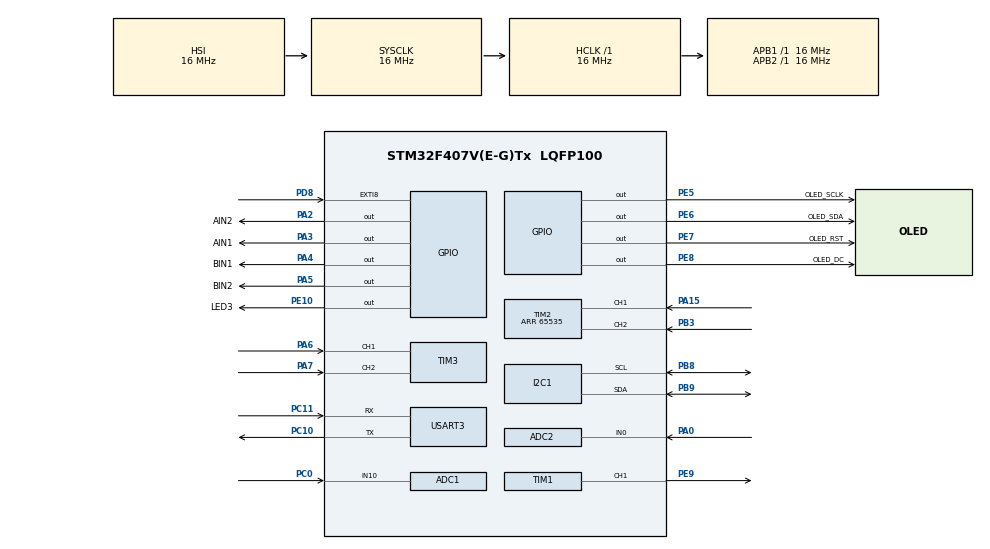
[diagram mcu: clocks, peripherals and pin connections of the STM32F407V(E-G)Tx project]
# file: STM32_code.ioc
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ADC1.Channel-1\#ChannelRegularConversion=ADC_CHANNEL_10
ADC1.Rank-1\#ChannelRegularConversion=1
ADC1.SamplingTime-1\#ChannelRegularConversion=ADC_SAMPLETIME_3CYCLES
ADC1.master=1
ADC2.Channel-0\#ChannelRegularConversion=ADC_CHANNEL_0
ADC2.NbrOfConversionFlag=1
ADC2.Rank-0\#ChannelRegularConversion=1
ADC2.SamplingTime-0\#ChannelRegularConversion=ADC_SAMPLETIME_3CYCLES
Dma.Request0=USART3_RX
Dma.Request1=USART3_TX
Dma.USART3_RX.0.Direction=DMA_PERIPH_TO_MEMORY
Dma.USART3_RX.0.FIFOMode=DMA_FIFOMODE_ENABLE
Dma.USART3_RX.0.FIFOThreshold=DMA_FIFO_THRESHOLD_FULL
Dma.USART3_RX.0.Instance=DMA1_Stream1
Dma.USART3_RX.0.MemBurst=DMA_MBURST_SINGLE
Dma.USART3_RX.0.MemDataAlignment=DMA_MDATAALIGN_BYTE
Dma.USART3_RX.0.MemInc=DMA_MINC_ENABLE
Dma.USART3_RX.0.Mode=DMA_NORMAL
Dma.USART3_RX.0.PeriphBurst=DMA_PBURST_SINGLE
Dma.USART3_RX.0.PeriphDataAlignment=DMA_PDATAALIGN_BYTE
Dma.USART3_RX.0.PeriphInc=DMA_PINC_DISABLE
Dma.USART3_RX.0.Priority=DMA_PRIORITY_LOW
Dma.USART3_TX.1.Direction=DMA_MEMORY_TO_PERIPH
Dma.USART3_TX.1.FIFOMode=DMA_FIFOMODE_ENABLE
Dma.USART3_TX.1.FIFOThreshold=DMA_FIFO_THRESHOLD_FULL
Dma.USART3_TX.1.Instance=DMA1_Stream3
Dma.USART3_TX.1.MemBurst=DMA_MBURST_SINGLE
Dma.USART3_TX.1.MemDataAlignment=DMA_MDATAALIGN_BYTE
Dma.USART3_TX.1.MemInc=DMA_MINC_ENABLE
Dma.USART3_TX.1.Mode=DMA_NORMAL
Dma.USART3_TX.1.PeriphBurst=DMA_PBURST_SINGLE
Dma.USART3_TX.1.PeriphDataAlignment=DMA_PDATAALIGN_BYTE
Dma.USART3_TX.1.PeriphInc=DMA_PINC_DISABLE
Dma.USART3_TX.1.Priority=DMA_PRIORITY_LOW
FREERTOS.Tasks01=defaultTask,24,256,StartDefaultTask,Default,NULL,Dynamic,NULL,NULL
FREERTOS.configENABLE_FPU=1
FREERTOS.configMINIMAL_STACK_SIZE=256
FREERTOS.configTOTAL_HEAP_SIZE=15360
FREERTOS.configUSE_NEWLIB_REENTRANT=1
FREERTOS.configUSE_PREEMPTION=0
I2C1.I2C_Mode=I2C_Fast
Mcu.Family=STM32F4
Mcu.Name=STM32F407V(E-G)Tx
Mcu.Package=LQFP100
NVIC.DMA1_Stream1_IRQn=true\:5\:0\:false\:false\:true\:true\:false\:true\:true
NVIC.DMA1_Stream3_IRQn=true\:5\:0\:false\:false\:true\:true\:false\:true\:true
NVIC.EXTI9_5_IRQn=true\:5\:0\:false\:false\:true\:true\:true\:true\:true
NVIC.PriorityGroup=NVIC_PRIORITYGROUP_4
NVIC.TIM7_IRQn=true\:15\:0\:false\:false\:true\:false\:false\:true\:true
NVIC.TimeBase=TIM7_IRQn
NVIC.TimeBaseIP=TIM7
NVIC.USART3_IRQn=true\:5\:0\:false\:false\:true\:true\:true\:true\:true
PA0-WKUP.Signal=ADCx_IN0
PA15.Signal=S_TIM2_CH1_ETR
PA2.GPIO_Label=AIN2
PA2.GPIO_Speed=GPIO_SPEED_FREQ_HIGH
PA2.Signal=GPIO_Output
PA3.GPIO_Label=AIN1
PA3.GPIO_Speed=GPIO_SPEED_FREQ_HIGH
PA3.Signal=GPIO_Output
PA4.GPIO_Label=BIN1
PA4.GPIO_Speed=GPIO_SPEED_FREQ_HIGH
PA4.Signal=GPIO_Output
PA5.GPIO_Label=BIN2
PA5.GPIO_Speed=GPIO_SPEED_FREQ_MEDIUM
PA5.Signal=GPIO_Output
PA6.Signal=S_TIM3_CH1
PA7.Signal=S_TIM3_CH2
PB3.Signal=S_TIM2_CH2
PB8.Mode=I2C
PB8.Signal=I2C1_SCL
PB9.Mode=I2C
PB9.Signal=I2C1_SDA
PC0.Signal=ADCx_IN10
PC10.GPIO_Speed=GPIO_SPEED_FREQ_HIGH
PC10.Mode=Asynchronous
PC10.Signal=USART3_TX
PC11.GPIO_ModeDefaultPP=GPIO_MODE_AF_PP
PC11.GPIO_PuPd=GPIO_PULLDOWN
PC11.GPIO_Speed=GPIO_SPEED_FREQ_HIGH
PC11.Mode=Asynchronous
PC11.Signal=USART3_RX
PC6.GPIO_Label=PWMA
PC6.Signal=S_TIM8_CH1
PC7.GPIO_Label=PWMB
PC7.Signal=S_TIM8_CH2
PD8.GPIO_ModeDefaultEXTI=GPIO_MODE_IT_FALLING
PD8.Signal=GPXTI8
PE10.GPIO_Label=LED3
PE10.GPIO_Speed=GPIO_SPEED_FREQ_MEDIUM
PE10.Signal=GPIO_Output
PE14.GPIO_Label=Servo
PE14.Signal=S_TIM1_CH4
PE5.GPIO_Label=OLED_SCLK
PE5.Signal=GPIO_Output
PE6.GPIO_Label=OLED_SDA
PE6.Signal=GPIO_Output
PE7.GPIO_Label=OLED_RST
PE7.Signal=GPIO_Output
PE8.GPIO_Label=OLED_DC
PE8.Signal=GPIO_Output
PE9.Signal=S_TIM1_CH1
ProjectManager.HeapSize=0x400
ProjectManager.StackSize=0x800
ProjectManager.TargetToolchain=STM32CubeIDE
RCC.48MHZClocksFreq_Value=48000000
RCC.AHBFreq_Value=16000000
RCC.APB1Freq_Value=16000000
RCC.APB1TimFreq_Value=16000000
RCC.APB2Freq_Value=16000000
RCC.APB2TimFreq_Value=16000000
RCC.CortexFreq_Value=16000000
RCC.HCLKFreq_Value=16000000
RCC.HSE_VALUE=8000000
RCC.HSI_VALUE=16000000
RCC.LSE_VALUE=32768
RCC.SYSCLKFreq_VALUE=16000000
RCC.VCOOutputFreq_Value=192000000
SH.ADCx_IN0.0=ADC2_IN0,IN0
SH.ADCx_IN10.0=ADC1_IN10,IN10
SH.S_TIM1_CH1.0=TIM1_CH1,PWM Generation1 CH1
SH.S_TIM1_CH4.0=TIM1_CH4
SH.S_TIM2_CH1_ETR.0=TIM2_CH1,Encoder_Interface
SH.S_TIM2_CH2.0=TIM2_CH2,Encoder_Interface
SH.S_TIM3_CH1.0=TIM3_CH1,Encoder_Interface
SH.S_TIM3_CH2.0=TIM3_CH2,Encoder_Interface
SH.S_TIM8_CH1.0=TIM8_CH1
SH.S_TIM8_CH2.0=TIM8_CH2
TIM1.AutoReloadPreload=TIM_AUTORELOAD_PRELOAD_ENABLE
TIM1.Channel-PWM\ Generation1\ CH1=TIM_CHANNEL_1
TIM1.Period=1000
TIM1.Prescaler=160
TIM2.EncoderMode=TIM_ENCODERMODE_TI12
TIM2.IC1Filter=10
TIM2.Period=65535
TIM3.EncoderMode=TIM_ENCODERMODE_TI12
TIM3.IC1Filter=10
TIM8.Channel-PWM\ Generation1\ No\ Output=TIM_CHANNEL_1
TIM8.Channel-PWM\ Generation2\ No\ Output=TIM_CHANNEL_2
TIM8.Period=7199
USART3.VirtualMode=VM_ASYNC
VP_FREERTOS_VS_CMSIS_V2.Mode=CMSIS_V2
VP_SYS_VS_tim7.Mode=TIM7
VP_TIM1_VS_ClockSourceINT.Mode=Internal
VP_TIM8_VS_ClockSourceINT.Mode=Internal
VP_TIM8_VS_no_output1.Mode=PWM Generation1 No Output
VP_TIM8_VS_no_output2.Mode=PWM Generation2 No Output
board=custom

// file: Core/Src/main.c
/* USER CODE BEGIN Header */
/**
 ******************************************************************************
 * @file           : main.c
 * @brief          : Main program body
 ******************************************************************************
 * @attention
 *
 * Copyright (c) 2024 STMicroelectronics.
 * All rights reserved.
 *
 * This software is licensed under terms that can be found in the LICENSE file
 * in the root directory of this software component.
 * If no LICENSE file comes with this software, it is provided AS-IS.
 *
 ******************************************************************************
 */
/* USER CODE END Header */
#include "main.h"
#include "cmsis_os.h"

/* USER CODE BEGIN PD */
ICM20948 imu;

/* USER CODE END PD */

ADC_HandleTypeDef hadc1;
ADC_HandleTypeDef hadc2;

I2C_HandleTypeDef hi2c1;

TIM_HandleTypeDef htim1;
TIM_HandleTypeDef htim2;
TIM_HandleTypeDef htim3;
TIM_HandleTypeDef htim8;

UART_HandleTypeDef huart3;
DMA_HandleTypeDef hdma_usart3_rx;
DMA_HandleTypeDef hdma_usart3_tx;

/* Definitions for defaultTask */
osThreadId_t defaultTaskHandle;
const osThreadAttr_t defaultTask_attributes = {
  .name = "defaultTask",
  .stack_size = 256 * 4,
  .priority = (osPriority_t) osPriorityNormal,
};
/* USER CODE BEGIN PV */

osThreadId_t sensorTaskHandle;
const osThreadAttr_t sensorTask_attr = { .name = "sensorTask", .stack_size =
		4096, .priority = (osPriority_t) osPriorityNormal, };

void sensorTask(void *pv);

/**
 * @brief  Retargets the C library printf function to the USART.
 * @param  None
 * @retval None
 */
#define PUTCHAR_PROTOTYPE int __io_putchar(int ch)
PUTCHAR_PROTOTYPE {
	/* Place your implementation of fputc here */
	/* e.g. write a character to the USART1 and Loop until the end of transmission */
	HAL_UART_Transmit(&huart3, (uint8_t*) &ch, 1, 0xFFFF);

	return ch;
}

/* USER CODE END PV */

void SystemClock_Config(void);
static void MX_GPIO_Init(void);
static void MX_DMA_Init(void);
static void MX_TIM8_Init(void);
static void MX_TIM1_Init(void);
static void MX_TIM2_Init(void);
static void MX_TIM3_Init(void);
static void MX_USART3_UART_Init(void);
static void MX_I2C1_Init(void);
static void MX_ADC1_Init(void);
static void MX_ADC2_Init(void);
void StartDefaultTask(void *argument);

int main(void)
{

  /* MCU Configuration--------------------------------------------------------*/

  /* Reset of all peripherals, Initializes the Flash interface and the Systick. */
  HAL_Init();

  /* Configure the system clock */
  SystemClock_Config();

  /* Initialize all configured peripherals */
  MX_GPIO_Init();
  MX_DMA_Init();
  MX_TIM8_Init();
  MX_TIM1_Init();
  MX_TIM2_Init();
  MX_TIM3_Init();
  MX_USART3_UART_Init();
  MX_I2C1_Init();
  MX_ADC1_Init();
  MX_ADC2_Init();
  /* USER CODE BEGIN 2 */

	defaultTaskHandle = osThreadNew(StartDefaultTask, NULL,
			&defaultTask_attributes);

	defaultTaskHandle = osThreadNew(sensorTask, NULL, &sensorTask_attr);
	initializeCPPconstructs();

	/**! FROM THIS POINT THE LOGIC CONTINUES IN APP_MAIN.CPP
	 *
	 * It is recommended to not use main.c..
	 * (1) The ioc code generation will overwrite parts if not careful to place them within USER CODE sections
	 * (2) The ioc code generation will not generate for c++ main file.
	 * **/

  /* USER CODE END 2 */

  /* Init scheduler */
  osKernelInitialize();
/* USER CODE BEGIN Header */
/**
 ******************************************************************************
 * @file           : main.c
 * @brief          : Main program body
 ******************************************************************************
 * @attention
 *
 * Copyright (c) 2024 STMicroelectronics.
 * All rights reserved.
 *
 * This software is licensed under terms that can be found in the LICENSE file
 * in the root directory of this software component.
 * If no LICENSE file comes with this software, it is provided AS-IS.
 *
 ******************************************************************************
 */
/* USER CODE END Header */

  /* Start scheduler */
  osKernelStart();

  /* We should never get here as control is now taken by the scheduler */
  /* Infinite loop */
	while (1) {

	}
}

void SystemClock_Config(void)
{
  RCC_OscInitTypeDef RCC_OscInitStruct = {0};
  RCC_ClkInitTypeDef RCC_ClkInitStruct = {0};

  /** Configure the main internal regulator output voltage
  */
  __HAL_RCC_PWR_CLK_ENABLE();
  __HAL_PWR_VOLTAGESCALING_CONFIG(PWR_REGULATOR_VOLTAGE_SCALE1);

  /** Initializes the RCC Oscillators according to the specified parameters
  * in the RCC_OscInitTypeDef structure.
  */
  RCC_OscInitStruct.OscillatorType = RCC_OSCILLATORTYPE_HSI;
  RCC_OscInitStruct.HSIState = RCC_HSI_ON;
  RCC_OscInitStruct.HSICalibrationValue = RCC_HSICALIBRATION_DEFAULT;
  RCC_OscInitStruct.PLL.PLLState = RCC_PLL_NONE;
  if (HAL_RCC_OscConfig(&RCC_OscInitStruct) != HAL_OK)
  {
    Error_Handler();
  }

  /** Initializes the CPU, AHB and APB buses clocks
  */
  RCC_ClkInitStruct.ClockType = RCC_CLOCKTYPE_HCLK|RCC_CLOCKTYPE_SYSCLK
                              |RCC_CLOCKTYPE_PCLK1|RCC_CLOCKTYPE_PCLK2;
  RCC_ClkInitStruct.SYSCLKSource = RCC_SYSCLKSOURCE_HSI;
  RCC_ClkInitStruct.AHBCLKDivider = RCC_SYSCLK_DIV1;
  RCC_ClkInitStruct.APB1CLKDivider = RCC_HCLK_DIV1;
  RCC_ClkInitStruct.APB2CLKDivider = RCC_HCLK_DIV1;

  if (HAL_RCC_ClockConfig(&RCC_ClkInitStruct, FLASH_LATENCY_0) != HAL_OK)
  {
    Error_Handler();
  }
}

static void MX_ADC1_Init(void)
{

  ADC_ChannelConfTypeDef sConfig = {0};

  /** Configure the global features of the ADC (Clock, Resolution, Data Alignment and number of conversion)
  */
  hadc1.Instance = ADC1;
  hadc1.Init.ClockPrescaler = ADC_CLOCK_SYNC_PCLK_DIV2;
  hadc1.Init.Resolution = ADC_RESOLUTION_12B;
  hadc1.Init.ScanConvMode = DISABLE;
  hadc1.Init.ContinuousConvMode = DISABLE;
  hadc1.Init.DiscontinuousConvMode = DISABLE;
  hadc1.Init.ExternalTrigConvEdge = ADC_EXTERNALTRIGCONVEDGE_NONE;
  hadc1.Init.ExternalTrigConv = ADC_SOFTWARE_START;
  hadc1.Init.DataAlign = ADC_DATAALIGN_RIGHT;
  hadc1.Init.NbrOfConversion = 1;
  hadc1.Init.DMAContinuousRequests = DISABLE;
  hadc1.Init.EOCSelection = ADC_EOC_SINGLE_CONV;
  if (HAL_ADC_Init(&hadc1) != HAL_OK)
  {
    Error_Handler();
  }

  /** Configure for the selected ADC regular channel its corresponding rank in the sequencer and its sample time.
  */
  sConfig.Channel = ADC_CHANNEL_10;
  sConfig.Rank = 1;
  sConfig.SamplingTime = ADC_SAMPLETIME_3CYCLES;
  if (HAL_ADC_ConfigChannel(&hadc1, &sConfig) != HAL_OK)
  {
    Error_Handler();
  }

}

static void MX_ADC2_Init(void)
{

  ADC_ChannelConfTypeDef sConfig = {0};

  /** Configure the global features of the ADC (Clock, Resolution, Data Alignment and number of conversion)
  */
  hadc2.Instance = ADC2;
  hadc2.Init.ClockPrescaler = ADC_CLOCK_SYNC_PCLK_DIV2;
  hadc2.Init.Resolution = ADC_RESOLUTION_12B;
  hadc2.Init.ScanConvMode = DISABLE;
  hadc2.Init.ContinuousConvMode = DISABLE;
  hadc2.Init.DiscontinuousConvMode = DISABLE;
  hadc2.Init.ExternalTrigConvEdge = ADC_EXTERNALTRIGCONVEDGE_NONE;
  hadc2.Init.ExternalTrigConv = ADC_SOFTWARE_START;
  hadc2.Init.DataAlign = ADC_DATAALIGN_RIGHT;
  hadc2.Init.NbrOfConversion = 1;
  hadc2.Init.DMAContinuousRequests = DISABLE;
  hadc2.Init.EOCSelection = ADC_EOC_SINGLE_CONV;
  if (HAL_ADC_Init(&hadc2) != HAL_OK)
  {
    Error_Handler();
  }

  /** Configure for the selected ADC regular channel its corresponding rank in the sequencer and its sample time.
  */
  sConfig.Channel = ADC_CHANNEL_0;
  sConfig.Rank = 1;
  sConfig.SamplingTime = ADC_SAMPLETIME_3CYCLES;
  if (HAL_ADC_ConfigChannel(&hadc2, &sConfig) != HAL_OK)
  {
    Error_Handler();
  }

}

static void MX_I2C1_Init(void)
{

  hi2c1.Instance = I2C1;
  hi2c1.Init.ClockSpeed = 400000;
  hi2c1.Init.DutyCycle = I2C_DUTYCYCLE_2;
  hi2c1.Init.OwnAddress1 = 0;
  hi2c1.Init.AddressingMode = I2C_ADDRESSINGMODE_7BIT;
  hi2c1.Init.DualAddressMode = I2C_DUALADDRESS_DISABLE;
  hi2c1.Init.OwnAddress2 = 0;
  hi2c1.Init.GeneralCallMode = I2C_GENERALCALL_DISABLE;
  hi2c1.Init.NoStretchMode = I2C_NOSTRETCH_DISABLE;
  if (HAL_I2C_Init(&hi2c1) != HAL_OK)
  {
    Error_Handler();
  }

}

static void MX_TIM1_Init(void)
{

  TIM_ClockConfigTypeDef sClockSourceConfig = {0};
  TIM_MasterConfigTypeDef sMasterConfig = {0};
  TIM_OC_InitTypeDef sConfigOC = {0};
  TIM_BreakDeadTimeConfigTypeDef sBreakDeadTimeConfig = {0};

  htim1.Instance = TIM1;
  htim1.Init.Prescaler = 160;
  htim1.Init.CounterMode = TIM_COUNTERMODE_UP;
  htim1.Init.Period = 1000;
  htim1.Init.ClockDivision = TIM_CLOCKDIVISION_DIV1;
  htim1.Init.RepetitionCounter = 0;
  htim1.Init.AutoReloadPreload = TIM_AUTORELOAD_PRELOAD_ENABLE;
  if (HAL_TIM_Base_Init(&htim1) != HAL_OK)
  {
    Error_Handler();
  }
  sClockSourceConfig.ClockSource = TIM_CLOCKSOURCE_INTERNAL;
  if (HAL_TIM_ConfigClockSource(&htim1, &sClockSourceConfig) != HAL_OK)
  {
    Error_Handler();
  }
  if (HAL_TIM_PWM_Init(&htim1) != HAL_OK)
  {
    Error_Handler();
  }
  sMasterConfig.MasterOutputTrigger = TIM_TRGO_RESET;
  sMasterConfig.MasterSlaveMode = TIM_MASTERSLAVEMODE_DISABLE;
  if (HAL_TIMEx_MasterConfigSynchronization(&htim1, &sMasterConfig) != HAL_OK)
  {
    Error_Handler();
  }
  sConfigOC.OCMode = TIM_OCMODE_PWM1;
  sConfigOC.Pulse = 0;
  sConfigOC.OCPolarity = TIM_OCPOLARITY_HIGH;
  sConfigOC.OCNPolarity = TIM_OCNPOLARITY_HIGH;
  sConfigOC.OCFastMode = TIM_OCFAST_DISABLE;
  sConfigOC.OCIdleState = TIM_OCIDLESTATE_RESET;
  sConfigOC.OCNIdleState = TIM_OCNIDLESTATE_RESET;
  if (HAL_TIM_PWM_ConfigChannel(&htim1, &sConfigOC, TIM_CHANNEL_1) != HAL_OK)
  {
    Error_Handler();
  }
  sBreakDeadTimeConfig.OffStateRunMode = TIM_OSSR_DISABLE;
  sBreakDeadTimeConfig.OffStateIDLEMode = TIM_OSSI_DISABLE;
  sBreakDeadTimeConfig.LockLevel = TIM_LOCKLEVEL_OFF;
  sBreakDeadTimeConfig.DeadTime = 0;
  sBreakDeadTimeConfig.BreakState = TIM_BREAK_DISABLE;
  sBreakDeadTimeConfig.BreakPolarity = TIM_BREAKPOLARITY_HIGH;
  sBreakDeadTimeConfig.AutomaticOutput = TIM_AUTOMATICOUTPUT_DISABLE;
  if (HAL_TIMEx_ConfigBreakDeadTime(&htim1, &sBreakDeadTimeConfig) != HAL_OK)
  {
    Error_Handler();
  }
  HAL_TIM_MspPostInit(&htim1);

}

static void MX_TIM2_Init(void)
{

  TIM_Encoder_InitTypeDef sConfig = {0};
  TIM_MasterConfigTypeDef sMasterConfig = {0};

  htim2.Instance = TIM2;
  htim2.Init.Prescaler = 0;
  htim2.Init.CounterMode = TIM_COUNTERMODE_UP;
  htim2.Init.Period = 65535;
  htim2.Init.ClockDivision = TIM_CLOCKDIVISION_DIV1;
  htim2.Init.AutoReloadPreload = TIM_AUTORELOAD_PRELOAD_DISABLE;
  sConfig.EncoderMode = TIM_ENCODERMODE_TI12;
  sConfig.IC1Polarity = TIM_ICPOLARITY_RISING;
  sConfig.IC1Selection = TIM_ICSELECTION_DIRECTTI;
  sConfig.IC1Prescaler = TIM_ICPSC_DIV1;
  sConfig.IC1Filter = 10;
  sConfig.IC2Polarity = TIM_ICPOLARITY_RISING;
  sConfig.IC2Selection = TIM_ICSELECTION_DIRECTTI;
  sConfig.IC2Prescaler = TIM_ICPSC_DIV1;
  sConfig.IC2Filter = 0;
  if (HAL_TIM_Encoder_Init(&htim2, &sConfig) != HAL_OK)
  {
    Error_Handler();
  }
  sMasterConfig.MasterOutputTrigger = TIM_TRGO_RESET;
  sMasterConfig.MasterSlaveMode = TIM_MASTERSLAVEMODE_DISABLE;
  if (HAL_TIMEx_MasterConfigSynchronization(&htim2, &sMasterConfig) != HAL_OK)
  {
    Error_Handler();
  }

}

static void MX_TIM3_Init(void)
{

  TIM_Encoder_InitTypeDef sConfig = {0};
  TIM_MasterConfigTypeDef sMasterConfig = {0};

  htim3.Instance = TIM3;
  htim3.Init.Prescaler = 0;
  htim3.Init.CounterMode = TIM_COUNTERMODE_UP;
  htim3.Init.Period = 65535;
  htim3.Init.ClockDivision = TIM_CLOCKDIVISION_DIV1;
  htim3.Init.AutoReloadPreload = TIM_AUTORELOAD_PRELOAD_DISABLE;
  sConfig.EncoderMode = TIM_ENCODERMODE_TI12;
  sConfig.IC1Polarity = TIM_ICPOLARITY_RISING;
  sConfig.IC1Selection = TIM_ICSELECTION_DIRECTTI;
  sConfig.IC1Prescaler = TIM_ICPSC_DIV1;
  sConfig.IC1Filter = 10;
  sConfig.IC2Polarity = TIM_ICPOLARITY_RISING;
  sConfig.IC2Selection = TIM_ICSELECTION_DIRECTTI;
  sConfig.IC2Prescaler = TIM_ICPSC_DIV1;
  sConfig.IC2Filter = 0;
  if (HAL_TIM_Encoder_Init(&htim3, &sConfig) != HAL_OK)
  {
    Error_Handler();
  }
  sMasterConfig.MasterOutputTrigger = TIM_TRGO_RESET;
  sMasterConfig.MasterSlaveMode = TIM_MASTERSLAVEMODE_DISABLE;
  if (HAL_TIMEx_MasterConfigSynchronization(&htim3, &sMasterConfig) != HAL_OK)
  {
    Error_Handler();
  }

}

static void MX_TIM8_Init(void)
{

  TIM_ClockConfigTypeDef sClockSourceConfig = {0};
  TIM_MasterConfigTypeDef sMasterConfig = {0};
  TIM_OC_InitTypeDef sConfigOC = {0};
  TIM_BreakDeadTimeConfigTypeDef sBreakDeadTimeConfig = {0};

  htim8.Instance = TIM8;
  htim8.Init.Prescaler = 0;
  htim8.Init.CounterMode = TIM_COUNTERMODE_UP;
  htim8.Init.Period = 7199;
  htim8.Init.ClockDivision = TIM_CLOCKDIVISION_DIV1;
  htim8.Init.RepetitionCounter = 0;
  htim8.Init.AutoReloadPreload = TIM_AUTORELOAD_PRELOAD_DISABLE;
  if (HAL_TIM_Base_Init(&htim8) != HAL_OK)
  {
    Error_Handler();
  }
  sClockSourceConfig.ClockSource = TIM_CLOCKSOURCE_INTERNAL;
  if (HAL_TIM_ConfigClockSource(&htim8, &sClockSourceConfig) != HAL_OK)
  {
    Error_Handler();
  }
  if (HAL_TIM_PWM_Init(&htim8) != HAL_OK)
  {
    Error_Handler();
  }
  sMasterConfig.MasterOutputTrigger = TIM_TRGO_RESET;
  sMasterConfig.MasterSlaveMode = TIM_MASTERSLAVEMODE_DISABLE;
  if (HAL_TIMEx_MasterConfigSynchronization(&htim8, &sMasterConfig) != HAL_OK)
  {
    Error_Handler();
  }
  sConfigOC.OCMode = TIM_OCMODE_PWM1;
  sConfigOC.Pulse = 0;
  sConfigOC.OCPolarity = TIM_OCPOLARITY_HIGH;
  sConfigOC.OCNPolarity = TIM_OCNPOLARITY_HIGH;
  sConfigOC.OCFastMode = TIM_OCFAST_DISABLE;
  sConfigOC.OCIdleState = TIM_OCIDLESTATE_RESET;
  sConfigOC.OCNIdleState = TIM_OCNIDLESTATE_RESET;
  if (HAL_TIM_PWM_ConfigChannel(&htim8, &sConfigOC, TIM_CHANNEL_1) != HAL_OK)
  {
    Error_Handler();
  }
  if (HAL_TIM_PWM_ConfigChannel(&htim8, &sConfigOC, TIM_CHANNEL_2) != HAL_OK)
  {
    Error_Handler();
  }
  sBreakDeadTimeConfig.OffStateRunMode = TIM_OSSR_DISABLE;
  sBreakDeadTimeConfig.OffStateIDLEMode = TIM_OSSI_DISABLE;
  sBreakDeadTimeConfig.LockLevel = TIM_LOCKLEVEL_OFF;
  sBreakDeadTimeConfig.DeadTime = 0;
  sBreakDeadTimeConfig.BreakState = TIM_BREAK_DISABLE;
  sBreakDeadTimeConfig.BreakPolarity = TIM_BREAKPOLARITY_HIGH;
  sBreakDeadTimeConfig.AutomaticOutput = TIM_AUTOMATICOUTPUT_DISABLE;
  if (HAL_TIMEx_ConfigBreakDeadTime(&htim8, &sBreakDeadTimeConfig) != HAL_OK)
  {
    Error_Handler();
  }

}

static void MX_USART3_UART_Init(void)
{

  huart3.Instance = USART3;
  huart3.Init.BaudRate = 115200;
  huart3.Init.WordLength = UART_WORDLENGTH_8B;
  huart3.Init.StopBits = UART_STOPBITS_1;
  huart3.Init.Parity = UART_PARITY_NONE;
  huart3.Init.Mode = UART_MODE_TX_RX;
  huart3.Init.HwFlowCtl = UART_HWCONTROL_NONE;
  huart3.Init.OverSampling = UART_OVERSAMPLING_16;
  if (HAL_UART_Init(&huart3) != HAL_OK)
  {
    Error_Handler();
  }

}

static void MX_DMA_Init(void)
{

  /* DMA controller clock enable */
  __HAL_RCC_DMA1_CLK_ENABLE();

  /* DMA interrupt init */
  /* DMA1_Stream1_IRQn interrupt configuration */
  HAL_NVIC_SetPriority(DMA1_Stream1_IRQn, 5, 0);
  HAL_NVIC_EnableIRQ(DMA1_Stream1_IRQn);
  /* DMA1_Stream3_IRQn interrupt configuration */
  HAL_NVIC_SetPriority(DMA1_Stream3_IRQn, 5, 0);
  HAL_NVIC_EnableIRQ(DMA1_Stream3_IRQn);

}

static void MX_GPIO_Init(void)
{
  GPIO_InitTypeDef GPIO_InitStruct = {0};

  /* GPIO Ports Clock Enable */
  __HAL_RCC_GPIOE_CLK_ENABLE();
  __HAL_RCC_GPIOC_CLK_ENABLE();
  __HAL_RCC_GPIOA_CLK_ENABLE();
  __HAL_RCC_GPIOD_CLK_ENABLE();
  __HAL_RCC_GPIOB_CLK_ENABLE();

  /*Configure GPIO pin Output Level */
  HAL_GPIO_WritePin(GPIOE, OLED_SCLK_Pin|OLED_SDA_Pin|OLED_RST_Pin|OLED_DC_Pin
                          |LED3_Pin, GPIO_PIN_RESET);

  /*Configure GPIO pin Output Level */
  HAL_GPIO_WritePin(GPIOA, AIN2_Pin|AIN1_Pin|BIN1_Pin|BIN2_Pin, GPIO_PIN_RESET);

  /*Configure GPIO pins : OLED_SCLK_Pin OLED_SDA_Pin OLED_RST_Pin OLED_DC_Pin */
  GPIO_InitStruct.Pin = OLED_SCLK_Pin|OLED_SDA_Pin|OLED_RST_Pin|OLED_DC_Pin;
  GPIO_InitStruct.Mode = GPIO_MODE_OUTPUT_PP;
  GPIO_InitStruct.Pull = GPIO_NOPULL;
  GPIO_InitStruct.Speed = GPIO_SPEED_FREQ_LOW;
  HAL_GPIO_Init(GPIOE, &GPIO_InitStruct);

  /*Configure GPIO pins : AIN2_Pin AIN1_Pin BIN1_Pin */
  GPIO_InitStruct.Pin = AIN2_Pin|AIN1_Pin|BIN1_Pin;
  GPIO_InitStruct.Mode = GPIO_MODE_OUTPUT_PP;
  GPIO_InitStruct.Pull = GPIO_NOPULL;
  GPIO_InitStruct.Speed = GPIO_SPEED_FREQ_HIGH;
  HAL_GPIO_Init(GPIOA, &GPIO_InitStruct);

  /*Configure GPIO pin : BIN2_Pin */
  GPIO_InitStruct.Pin = BIN2_Pin;
  GPIO_InitStruct.Mode = GPIO_MODE_OUTPUT_PP;
  GPIO_InitStruct.Pull = GPIO_NOPULL;
  GPIO_InitStruct.Speed = GPIO_SPEED_FREQ_MEDIUM;
  HAL_GPIO_Init(BIN2_GPIO_Port, &GPIO_InitStruct);

  /*Configure GPIO pin : LED3_Pin */
  GPIO_InitStruct.Pin = LED3_Pin;
  GPIO_InitStruct.Mode = GPIO_MODE_OUTPUT_PP;
  GPIO_InitStruct.Pull = GPIO_NOPULL;
  GPIO_InitStruct.Speed = GPIO_SPEED_FREQ_MEDIUM;
  HAL_GPIO_Init(LED3_GPIO_Port, &GPIO_InitStruct);

  /*Configure GPIO pin : PD8 */
  GPIO_InitStruct.Pin = GPIO_PIN_8;
  GPIO_InitStruct.Mode = GPIO_MODE_IT_FALLING;
  GPIO_InitStruct.Pull = GPIO_NOPULL;
  HAL_GPIO_Init(GPIOD, &GPIO_InitStruct);

  /* EXTI interrupt init*/
  HAL_NVIC_SetPriority(EXTI9_5_IRQn, 5, 0);
  HAL_NVIC_EnableIRQ(EXTI9_5_IRQn);

}

void StartDefaultTask(void *argument)
{
  /* USER CODE BEGIN 5 */
	/* Infinite loop */

	for (;;) {

		//OLED_Refresh_Gram(); // Refresh Ram
		osDelay(50);
	}
  /* USER CODE END 5 */
}

void HAL_TIM_PeriodElapsedCallback(TIM_HandleTypeDef *htim)
{
  if (htim->Instance == TIM7) {
    HAL_IncTick();
  }
}

void Error_Handler(void)
{
	__disable_irq();
	while (1) {
	}
}
